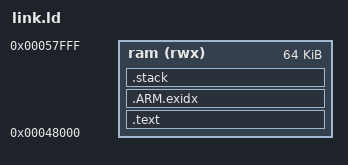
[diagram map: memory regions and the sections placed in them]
/* SPDX-License-Identifier: Apache-2.0 */

OUTPUT_FORMAT("elf32-littlearm", "elf32-littlearm", "elf32-littlearm")
OUTPUT_ARCH(arm)
SEARCH_DIR(.)

/* Memory Spaces Definitions */
MEMORY
{
  ram   (rwx) : ORIGIN = 0x48000, LENGTH = 0x10000 /* SRAMC. */
}

/* The stack size used by the application. NOTE: you need to adjust according to your application. */
STACK_SIZE = 0x1000; /* 4KB */

/* Section Definitions */
SECTIONS
{
    .text :
    {
        . = ALIGN(4);
        PROVIDE(__spl_start = .);
        .obj/source/start.o (*.text)
        *(.text .text.*)
        KEEP(*(.note.gnu.build-id))
        . = ALIGN(4);
    } > ram

    . = ALIGN(4);

    .ARM.exidx : {
        __exidx_start = .;
        *(.ARM.exidx* .gnu.linkonce.armexidx.*)
        __exidx_end = .;
    } > ram

    PROVIDE(__spl_end = .);
    PROVIDE(__spl_size = __spl_end - __spl_start);

    .stack (NOLOAD):
    {
        . = ALIGN(8);
        /* SRV stack section */
        __stack_srv_start = .;
        . += STACK_SIZE;
        __stack_srv_end = .;
    } > ram

    . = ALIGN(4);
    _end = . ;
}
